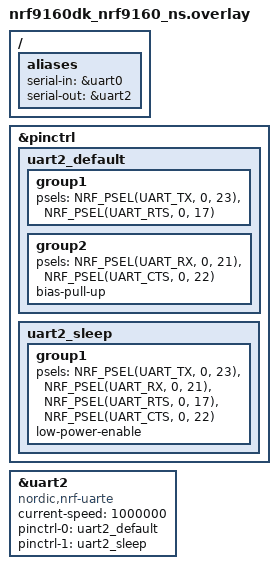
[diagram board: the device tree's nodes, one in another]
/*
    | nRF9160     |                            |    nRF52840    |
    | RTS   P0.17 | -- nRF interface line 0 -- | P0.17  CTS     |
    |       P0.18 | -- nRF interface line 1 -- | P0.20          |
    |       P0.19 | -- nRF interface line 2 -- | P0.15          |
    | RX    P0.21 | -- nRF interface line 3 -- | P0.22  TX      |
    | CTS   P0.22 | -- nRF interface line 4 -- | P1.04  RTS     |
    | TX    P0.23 | -- nRF interface line 5 -- | P1.02  RX      |
    |       COEX0 | -- nRF interface line 6 -- | P1.13          |
    |       COEX1 | -- nRF interface line 7 -- | P1.11          |
    |       COEX2 | -- nRF interface line 8 -- | P1.15          |
    |       P0.24 | -- nRF interface line 9 -- | P0.18 (nRESET) | (in v0.14.0 or later)
*/


&pinctrl {
	uart2_default: uart2_default {
		group1 {
			psels = <NRF_PSEL(UART_TX, 0, 23)>,
				<NRF_PSEL(UART_RTS, 0, 17)>;
		};
		group2 {
			psels = <NRF_PSEL(UART_RX, 0, 21)>,
				<NRF_PSEL(UART_CTS, 0, 22)>;
			bias-pull-up;
		};
	};

	uart2_sleep: uart2_sleep {
		group1 {
			psels =<NRF_PSEL(UART_TX, 0, 23)>,
				<NRF_PSEL(UART_RX, 0, 21)>,
				<NRF_PSEL(UART_RTS, 0, 17)>,
				<NRF_PSEL(UART_CTS, 0, 22)>;
			low-power-enable;
		};
	};

};


&uart2 {
	compatible = "nordic,nrf-uarte";
	current-speed = <1000000>;
	status = "okay";
	pinctrl-0 = <&uart2_default>;
	pinctrl-1 = <&uart2_sleep>;
	pinctrl-names = "default", "sleep";
};

/ {
	aliases {
		serial-in = &uart0;
		serial-out = &uart2;
	};
};
